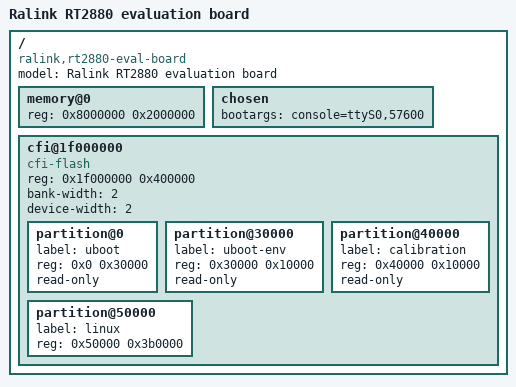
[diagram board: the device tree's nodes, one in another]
/dts-v1/;

/include/ "rt2880.dtsi"

/ {
	compatible = "ralink,rt2880-eval-board", "ralink,rt2880-soc";
	model = "Ralink RT2880 evaluation board";

	memory@0 {
		device_type = "memory";
		reg = <0x8000000 0x2000000>;
	};

	chosen {
		bootargs = "console=ttyS0,57600";
	};

	cfi@1f000000 {
		compatible = "cfi-flash";
		reg = <0x1f000000 0x400000>;

		bank-width = <2>;
		device-width = <2>;
		#address-cells = <1>;
		#size-cells = <1>;

		partition@0 {
			label = "uboot";
			reg = <0x0 0x30000>;
			read-only;
		};
		partition@30000 {
			label = "uboot-env";
			reg = <0x30000 0x10000>;
			read-only;
		};
		partition@40000 {
			label = "calibration";
			reg = <0x40000 0x10000>;
			read-only;
		};
		partition@50000 {
			label = "linux";
			reg = <0x50000 0x3b0000>;
		};
	};
};
